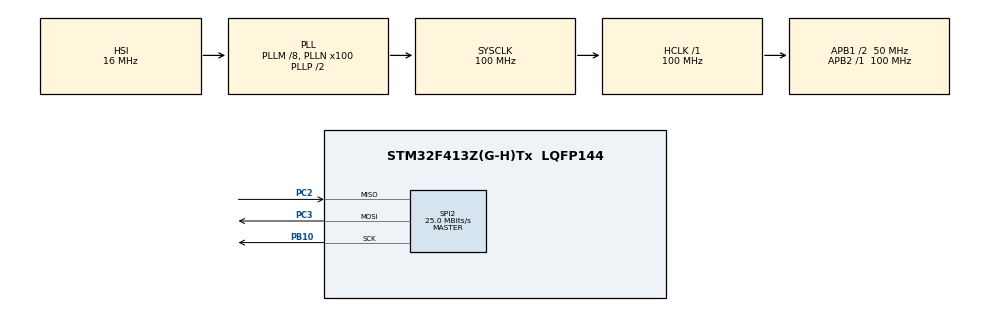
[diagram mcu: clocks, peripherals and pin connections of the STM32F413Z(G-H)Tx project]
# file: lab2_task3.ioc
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Mcu.Family=STM32F4
Mcu.Name=STM32F413Z(G-H)Tx
Mcu.Package=LQFP144
NVIC.PriorityGroup=NVIC_PRIORITYGROUP_4
PB10.Mode=Full_Duplex_Master
PB10.Signal=SPI2_SCK
PC2.Mode=Full_Duplex_Master
PC2.Signal=SPI2_MISO
PC3.Mode=Full_Duplex_Master
PC3.Signal=SPI2_MOSI
ProjectManager.HeapSize=0x200
ProjectManager.StackSize=0x400
ProjectManager.TargetToolchain=STM32CubeIDE
RCC.AHBFreq_Value=100000000
RCC.APB1CLKDivider=RCC_HCLK_DIV2
RCC.APB1Freq_Value=50000000
RCC.APB1TimFreq_Value=100000000
RCC.APB2Freq_Value=100000000
RCC.APB2TimFreq_Value=100000000
RCC.CortexFreq_Value=100000000
RCC.HCLKFreq_Value=100000000
RCC.PLLM=8
RCC.PLLN=100
RCC.SYSCLKFreq_VALUE=100000000
RCC.SYSCLKSource=RCC_SYSCLKSOURCE_PLLCLK
RCC.USBFreq_Value=100000000
RCC.VCOOutputFreq_Value=200000000
SPI2.BaudRatePrescaler=SPI_BAUDRATEPRESCALER_2
SPI2.CalculateBaudRate=25.0 MBits/s
SPI2.Direction=SPI_DIRECTION_2LINES
SPI2.Mode=SPI_MODE_MASTER
SPI2.VirtualType=VM_MASTER
board=custom

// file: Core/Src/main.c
/* USER CODE BEGIN Header */
/**
  ******************************************************************************
  * @file           : main.c
  * @brief          : Main program body
  ******************************************************************************
  * @attention
  *
  * <h2><center>&copy; Copyright (c) 2020 STMicroelectronics.
  * All rights reserved.</center></h2>
  *
  * This software component is licensed by ST under BSD 3-Clause license,
  * the "License"; You may not use this file except in compliance with the
  * License. You may obtain a copy of the License at:
  *                        opensource.org/licenses/BSD-3-Clause
  *
  ******************************************************************************
  */
/* USER CODE END Header */

#include "main.h"

SPI_HandleTypeDef hspi2;

/* USER CODE BEGIN PV */
uint8_t tx_buffer[] = {0,1,2,3,4,5,6,7,8,9};
uint8_t rx_buffer[10];
/* USER CODE END PV */

void SystemClock_Config(void);
static void MX_GPIO_Init(void);
static void MX_SPI2_Init(void);

int main(void)
{

  /* MCU Configuration--------------------------------------------------------*/

  /* Reset of all peripherals, Initializes the Flash interface and the Systick. */
  HAL_Init();

  /* Configure the system clock */
  SystemClock_Config();

  /* Initialize all configured peripherals */
  MX_GPIO_Init();
  MX_SPI2_Init();

  /* Infinite loop */
  while (1)
  {
	  HAL_SPI_TransmitReceive(&hspi2, tx_buffer, rx_buffer, 10, 100);
  }
}

void SystemClock_Config(void)
{
  RCC_OscInitTypeDef RCC_OscInitStruct = {0};
  RCC_ClkInitTypeDef RCC_ClkInitStruct = {0};

  /** Configure the main internal regulator output voltage
  */
  __HAL_RCC_PWR_CLK_ENABLE();
  __HAL_PWR_VOLTAGESCALING_CONFIG(PWR_REGULATOR_VOLTAGE_SCALE1);
  /** Initializes the CPU, AHB and APB busses clocks
  */
  RCC_OscInitStruct.OscillatorType = RCC_OSCILLATORTYPE_HSI;
  RCC_OscInitStruct.HSIState = RCC_HSI_ON;
  RCC_OscInitStruct.HSICalibrationValue = RCC_HSICALIBRATION_DEFAULT;
  RCC_OscInitStruct.PLL.PLLState = RCC_PLL_ON;
  RCC_OscInitStruct.PLL.PLLSource = RCC_PLLSOURCE_HSI;
  RCC_OscInitStruct.PLL.PLLM = 8;
  RCC_OscInitStruct.PLL.PLLN = 100;
  RCC_OscInitStruct.PLL.PLLP = RCC_PLLP_DIV2;
  RCC_OscInitStruct.PLL.PLLQ = 2;
  RCC_OscInitStruct.PLL.PLLR = 2;
  if (HAL_RCC_OscConfig(&RCC_OscInitStruct) != HAL_OK)
  {
    Error_Handler();
  }
  /** Initializes the CPU, AHB and APB busses clocks
  */
  RCC_ClkInitStruct.ClockType = RCC_CLOCKTYPE_HCLK|RCC_CLOCKTYPE_SYSCLK
                              |RCC_CLOCKTYPE_PCLK1|RCC_CLOCKTYPE_PCLK2;
  RCC_ClkInitStruct.SYSCLKSource = RCC_SYSCLKSOURCE_PLLCLK;
  RCC_ClkInitStruct.AHBCLKDivider = RCC_SYSCLK_DIV1;
  RCC_ClkInitStruct.APB1CLKDivider = RCC_HCLK_DIV2;
  RCC_ClkInitStruct.APB2CLKDivider = RCC_HCLK_DIV1;

  if (HAL_RCC_ClockConfig(&RCC_ClkInitStruct, FLASH_LATENCY_3) != HAL_OK)
  {
    Error_Handler();
  }
}

static void MX_SPI2_Init(void)
{

  /* SPI2 parameter configuration*/
  hspi2.Instance = SPI2;
  hspi2.Init.Mode = SPI_MODE_MASTER;
  hspi2.Init.Direction = SPI_DIRECTION_2LINES;
  hspi2.Init.DataSize = SPI_DATASIZE_8BIT;
  hspi2.Init.CLKPolarity = SPI_POLARITY_LOW;
  hspi2.Init.CLKPhase = SPI_PHASE_1EDGE;
  hspi2.Init.NSS = SPI_NSS_SOFT;
  hspi2.Init.BaudRatePrescaler = SPI_BAUDRATEPRESCALER_2;
  hspi2.Init.FirstBit = SPI_FIRSTBIT_MSB;
  hspi2.Init.TIMode = SPI_TIMODE_DISABLE;
  hspi2.Init.CRCCalculation = SPI_CRCCALCULATION_DISABLE;
  hspi2.Init.CRCPolynomial = 10;
  if (HAL_SPI_Init(&hspi2) != HAL_OK)
  {
    Error_Handler();
  }

}

static void MX_GPIO_Init(void)
{

  /* GPIO Ports Clock Enable */
  __HAL_RCC_GPIOC_CLK_ENABLE();
  __HAL_RCC_GPIOB_CLK_ENABLE();

}

void Error_Handler(void)
{
}

/************************ (C) COPYRIGHT STMicroelectronics *****END OF FILE****/
